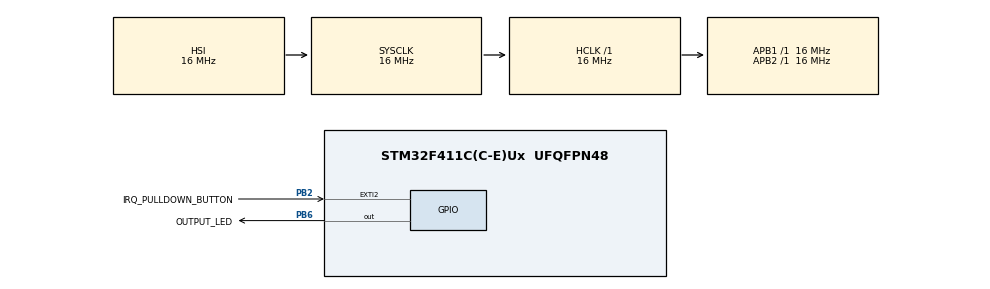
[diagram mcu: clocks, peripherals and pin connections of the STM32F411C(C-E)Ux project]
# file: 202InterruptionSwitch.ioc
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Mcu.Family=STM32F4
Mcu.Name=STM32F411C(C-E)Ux
Mcu.Package=UFQFPN48
NVIC.EXTI2_IRQn=true\:0\:0\:false\:false\:true\:true\:true\:true
NVIC.PriorityGroup=NVIC_PRIORITYGROUP_4
PA13.Mode=Serial_Wire
PA13.Signal=SYS_JTMS-SWDIO
PA14.Mode=Serial_Wire
PA14.Signal=SYS_JTCK-SWCLK
PB2.GPIO_Label=IRQ_PULLDOWN_BUTTON
PB2.Signal=GPXTI2
PB6.GPIO_Label=OUTPUT_LED
PB6.Signal=GPIO_Output
ProjectManager.HeapSize=0x200
ProjectManager.StackSize=0x400
ProjectManager.TargetToolchain=STM32CubeIDE
RCC.AHBFreq_Value=16000000
RCC.APB1Freq_Value=16000000
RCC.APB2Freq_Value=16000000
RCC.CortexFreq_Value=16000000
RCC.HSE_VALUE=25000000
RCC.HSI_VALUE=16000000
RCC.LSE_VALUE=32768
RCC.SYSCLKFreq_VALUE=16000000
RCC.VCOOutputFreq_Value=192000000
board=custom

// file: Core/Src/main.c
/* USER CODE BEGIN Header */
/**
  ******************************************************************************
  * @file           : main.c
  * @brief          : Main program body
  ******************************************************************************
  * @attention
  *
  * Copyright (c) 2025 STMicroelectronics.
  * All rights reserved.
  *
  * This software is licensed under terms that can be found in the LICENSE file
  * in the root directory of this software component.
  * If no LICENSE file comes with this software, it is provided AS-IS.
  *
  ******************************************************************************
  */
/* USER CODE END Header */
#include "main.h"

void SystemClock_Config(void);
static void MX_GPIO_Init(void);

int main(void)
{

  /* MCU Configuration--------------------------------------------------------*/

  /* Reset of all peripherals, Initializes the Flash interface and the Systick. */
  HAL_Init();

  /* Configure the system clock */
  SystemClock_Config();

  /* Initialize all configured peripherals */
  MX_GPIO_Init();

  /* Infinite loop */
  while (1)
  {

  }
}

void SystemClock_Config(void)
{
  RCC_OscInitTypeDef RCC_OscInitStruct = {0};
  RCC_ClkInitTypeDef RCC_ClkInitStruct = {0};

  /** Configure the main internal regulator output voltage
  */
  __HAL_RCC_PWR_CLK_ENABLE();
  __HAL_PWR_VOLTAGESCALING_CONFIG(PWR_REGULATOR_VOLTAGE_SCALE1);

  /** Initializes the RCC Oscillators according to the specified parameters
  * in the RCC_OscInitTypeDef structure.
  */
  RCC_OscInitStruct.OscillatorType = RCC_OSCILLATORTYPE_HSI;
  RCC_OscInitStruct.HSIState = RCC_HSI_ON;
  RCC_OscInitStruct.HSICalibrationValue = RCC_HSICALIBRATION_DEFAULT;
  RCC_OscInitStruct.PLL.PLLState = RCC_PLL_NONE;
  if (HAL_RCC_OscConfig(&RCC_OscInitStruct) != HAL_OK)
  {
    Error_Handler();
  }

  /** Initializes the CPU, AHB and APB buses clocks
  */
  RCC_ClkInitStruct.ClockType = RCC_CLOCKTYPE_HCLK|RCC_CLOCKTYPE_SYSCLK
                              |RCC_CLOCKTYPE_PCLK1|RCC_CLOCKTYPE_PCLK2;
  RCC_ClkInitStruct.SYSCLKSource = RCC_SYSCLKSOURCE_HSI;
  RCC_ClkInitStruct.AHBCLKDivider = RCC_SYSCLK_DIV1;
  RCC_ClkInitStruct.APB1CLKDivider = RCC_HCLK_DIV1;
  RCC_ClkInitStruct.APB2CLKDivider = RCC_HCLK_DIV1;

  if (HAL_RCC_ClockConfig(&RCC_ClkInitStruct, FLASH_LATENCY_0) != HAL_OK)
  {
    Error_Handler();
  }
}

static void MX_GPIO_Init(void)
{
  GPIO_InitTypeDef GPIO_InitStruct = {0};

  /* GPIO Ports Clock Enable */
  __HAL_RCC_GPIOB_CLK_ENABLE();
  __HAL_RCC_GPIOA_CLK_ENABLE();

  /*Configure GPIO pin Output Level */
  HAL_GPIO_WritePin(OUTPUT_LED_GPIO_Port, OUTPUT_LED_Pin, GPIO_PIN_RESET);

  /*Configure GPIO pin : IRQ_PULLDOWN_BUTTON_Pin */
  GPIO_InitStruct.Pin = IRQ_PULLDOWN_BUTTON_Pin;
  GPIO_InitStruct.Mode = GPIO_MODE_IT_RISING;
  GPIO_InitStruct.Pull = GPIO_NOPULL;
  HAL_GPIO_Init(IRQ_PULLDOWN_BUTTON_GPIO_Port, &GPIO_InitStruct);

  /*Configure GPIO pin : OUTPUT_LED_Pin */
  GPIO_InitStruct.Pin = OUTPUT_LED_Pin;
  GPIO_InitStruct.Mode = GPIO_MODE_OUTPUT_PP;
  GPIO_InitStruct.Pull = GPIO_NOPULL;
  GPIO_InitStruct.Speed = GPIO_SPEED_FREQ_LOW;
  HAL_GPIO_Init(OUTPUT_LED_GPIO_Port, &GPIO_InitStruct);

  /* EXTI interrupt init*/
  HAL_NVIC_SetPriority(EXTI2_IRQn, 0, 0);
  HAL_NVIC_EnableIRQ(EXTI2_IRQn);

}

/* USER CODE BEGIN 4 */
#define DEBOUNCE_DELAY 200 // Tiempo de debounce en milisegundos

uint32_t last_interrupt_time = 0;

void HAL_GPIO_EXTI_Callback(uint16_t GPIO_Pin)
{

	uint32_t current_time = HAL_GetTick(); // Obtiene el tiempo actual en milisegundos

//	if (GPIO_Pin == IRQ_PULLDOWN_BUTTON_Pin) // Verifica el pin que generó la interrupción
//	{
		if ((current_time - last_interrupt_time) > DEBOUNCE_DELAY) // Verifica el tiempo de debounce
		{
		  HAL_GPIO_TogglePin(GPIOB, OUTPUT_LED_Pin); // Alterna el estado del LED
		  last_interrupt_time = current_time; // Actualiza el tiempo de la última interrupción
		}
//	}

}
/* USER CODE END 4 */

void Error_Handler(void)
{
  __disable_irq();
  while (1)
  {
  }
}
